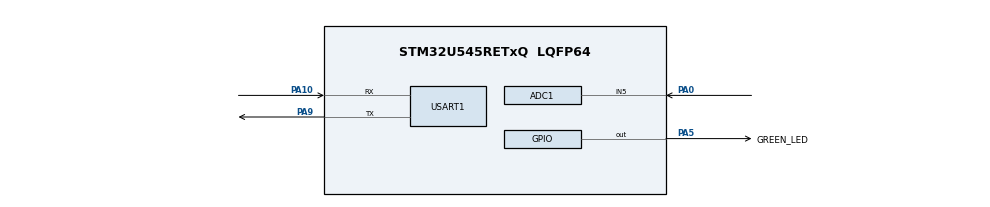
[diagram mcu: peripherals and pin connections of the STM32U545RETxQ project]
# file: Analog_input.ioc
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ADC1.Channel-0\#ChannelRegularConversion=ADC_CHANNEL_5
ADC1.MonitoredBy-0\#ChannelRegularConversion=__NULL
ADC1.NbrOfConversionFlag=1
ADC1.OffsetNumber-0\#ChannelRegularConversion=ADC_OFFSET_NONE
ADC1.Rank-0\#ChannelRegularConversion=1
ADC1.SamplingTime-0\#ChannelRegularConversion=ADC_SAMPLETIME_36CYCLES
ADC1.master=1
CORTEX_M33_NS.userName=CORTEX_M33
Mcu.Family=STM32U5
Mcu.Name=STM32U545RETxQ
Mcu.Package=LQFP64
NVIC.PriorityGroup=NVIC_PRIORITYGROUP_4
PA0.Mode=IN5-Single-Ended
PA0.Signal=ADC1_IN5
PA10.Mode=Asynchronous
PA10.Signal=USART1_RX
PA5.GPIO_Label=GREEN_LED
PA5.Signal=GPIO_Output
PA9.Mode=Asynchronous
PA9.Signal=USART1_TX
PWR.PowerMode=PWR_SMPS_SUPPLY
ProjectManager.HeapSize=0x200
ProjectManager.StackSize=0x400
ProjectManager.TargetToolchain=STM32CubeIDE
RCC.ADCFreq_Value=16000000
RCC.DACCLockSelectionVirtual=RCC_DAC1CLKSOURCE_LSI
RCC.DACCLockSelectionVirtualString=RCC_DAC1CLKSOURCE_LSI
RCC.EPOD_VALUE=4000000
RCC.HSE_VALUE=16000000
RCC.HSI48_VALUE=48000000
RCC.HSI_VALUE=16000000
RCC.LSE_VALUE=32768
RCC.LSIDIV_VALUE=32000
RCC.MSI_VALUE=4000000
RCC.USBFreq_Value=48000000
RCC.VCOOutputFreq_Value=516000000
USART1.VirtualMode-Asynchronous=VM_ASYNC
VP_ICACHE_VS_ICACHE.Mode=DirectMappedCache
VP_LPBAMQUEUE_VS_QUEUE.Mode=QUEUEMODE
VP_MEMORYMAP_VS_MEMORYMAP.Mode=CurAppReg
VP_NUCLEO-U545RE-Q_VS_BSP_COMMON.Mode=COMMON
VP_PWR_VS_LPOM.Mode=PowerOptimisation
VP_PWR_VS_SECSignals.Mode=Security/Privilege
VP_PWR_Vdda.Mode=isolationVdda
board=NUCLEO-U545RE-Q

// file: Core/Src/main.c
/* USER CODE BEGIN Header */
/**
  ******************************************************************************
  * @file           : main.c
  * @brief          : Main program body
  ******************************************************************************
  * @attention
  *
  * Copyright (c) 2026 STMicroelectronics.
  * All rights reserved.
  *
  * This software is licensed under terms that can be found in the LICENSE file
  * in the root directory of this software component.
  * If no LICENSE file comes with this software, it is provided AS-IS.
  *
  ******************************************************************************
  */
/* USER CODE END Header */
#include "main.h"

/* USER CODE BEGIN Includes */
#include <string.h>
#include <stdio.h>
/* USER CODE END Includes */

ADC_HandleTypeDef hadc1;

UART_HandleTypeDef huart1;

/* USER CODE BEGIN PV */
uint16_t measure = 0;
char msg[20];
/* USER CODE END PV */

void SystemClock_Config(void);
static void SystemPower_Config(void);
static void MX_GPIO_Init(void);
static void MX_ADC1_Init(void);
static void MX_ICACHE_Init(void);
static void MX_USART1_UART_Init(void);

int main(void)
{

  /* MCU Configuration--------------------------------------------------------*/

  /* Reset of all peripherals, Initializes the Flash interface and the Systick. */
  HAL_Init();

  /* Configure the System Power */
  SystemPower_Config();

  /* Configure the system clock */
  SystemClock_Config();

  /* Initialize all configured peripherals */
  MX_GPIO_Init();
  MX_ADC1_Init();
  MX_ICACHE_Init();
  MX_USART1_UART_Init();

  /* Infinite loop */
  while (1)
  {

    /* USER CODE BEGIN 3 */
	  HAL_ADC_Start(&hadc1);
	  HAL_ADC_PollForConversion(&hadc1, 20);
	  measure = HAL_ADC_GetValue(&hadc1);
	  sprintf(msg, "Value read: %hu\r\n", measure);
	  HAL_UART_Transmit(&huart1 , (uint8_t *)msg, strlen(msg), HAL_MAX_DELAY);
	  HAL_Delay(50);

  }
  /* USER CODE END 3 */
}

void SystemClock_Config(void)
{
  RCC_OscInitTypeDef RCC_OscInitStruct = {0};
  RCC_ClkInitTypeDef RCC_ClkInitStruct = {0};

  /** Configure the main internal regulator output voltage
  */
  if (HAL_PWREx_ControlVoltageScaling(PWR_REGULATOR_VOLTAGE_SCALE4) != HAL_OK)
  {
    Error_Handler();
  }

  /** Initializes the CPU, AHB and APB buses clocks
  */
  RCC_OscInitStruct.OscillatorType = RCC_OSCILLATORTYPE_HSI|RCC_OSCILLATORTYPE_MSI;
  RCC_OscInitStruct.HSIState = RCC_HSI_ON;
  RCC_OscInitStruct.HSICalibrationValue = RCC_HSICALIBRATION_DEFAULT;
  RCC_OscInitStruct.MSIState = RCC_MSI_ON;
  RCC_OscInitStruct.MSICalibrationValue = RCC_MSICALIBRATION_DEFAULT;
  RCC_OscInitStruct.MSIClockRange = RCC_MSIRANGE_4;
  RCC_OscInitStruct.PLL.PLLState = RCC_PLL_NONE;
  if (HAL_RCC_OscConfig(&RCC_OscInitStruct) != HAL_OK)
  {
    Error_Handler();
  }

  /** Initializes the CPU, AHB and APB buses clocks
  */
  RCC_ClkInitStruct.ClockType = RCC_CLOCKTYPE_HCLK|RCC_CLOCKTYPE_SYSCLK
                              |RCC_CLOCKTYPE_PCLK1|RCC_CLOCKTYPE_PCLK2
                              |RCC_CLOCKTYPE_PCLK3;
  RCC_ClkInitStruct.SYSCLKSource = RCC_SYSCLKSOURCE_MSI;
  RCC_ClkInitStruct.AHBCLKDivider = RCC_SYSCLK_DIV1;
  RCC_ClkInitStruct.APB1CLKDivider = RCC_HCLK_DIV1;
  RCC_ClkInitStruct.APB2CLKDivider = RCC_HCLK_DIV1;
  RCC_ClkInitStruct.APB3CLKDivider = RCC_HCLK_DIV1;

  if (HAL_RCC_ClockConfig(&RCC_ClkInitStruct, FLASH_LATENCY_0) != HAL_OK)
  {
    Error_Handler();
  }
}

/**
  * @brief Power Configuration
  * @retval None
  */
static void SystemPower_Config(void)
{

  /*
   * Switch to SMPS regulator instead of LDO
   */
  if (HAL_PWREx_ConfigSupply(PWR_SMPS_SUPPLY) != HAL_OK)
  {
    Error_Handler();
  }
}

static void MX_ADC1_Init(void)
{

  ADC_ChannelConfTypeDef sConfig = {0};

  /** Common config
  */
  hadc1.Instance = ADC1;
  hadc1.Init.ClockPrescaler = ADC_CLOCK_ASYNC_DIV1;
  hadc1.Init.Resolution = ADC_RESOLUTION_14B;
  hadc1.Init.GainCompensation = 0;
  hadc1.Init.DataAlign = ADC_DATAALIGN_RIGHT;
  hadc1.Init.ScanConvMode = ADC_SCAN_DISABLE;
  hadc1.Init.EOCSelection = ADC_EOC_SINGLE_CONV;
  hadc1.Init.LowPowerAutoWait = DISABLE;
  hadc1.Init.ContinuousConvMode = DISABLE;
  hadc1.Init.NbrOfConversion = 1;
  hadc1.Init.DiscontinuousConvMode = DISABLE;
  hadc1.Init.ExternalTrigConv = ADC_SOFTWARE_START;
  hadc1.Init.ExternalTrigConvEdge = ADC_EXTERNALTRIGCONVEDGE_NONE;
  hadc1.Init.DMAContinuousRequests = DISABLE;
  hadc1.Init.TriggerFrequencyMode = ADC_TRIGGER_FREQ_HIGH;
  hadc1.Init.Overrun = ADC_OVR_DATA_PRESERVED;
  hadc1.Init.LeftBitShift = ADC_LEFTBITSHIFT_NONE;
  hadc1.Init.ConversionDataManagement = ADC_CONVERSIONDATA_DR;
  hadc1.Init.OversamplingMode = DISABLE;
  if (HAL_ADC_Init(&hadc1) != HAL_OK)
  {
    Error_Handler();
  }

  /** Configure Regular Channel
  */
  sConfig.Channel = ADC_CHANNEL_5;
  sConfig.Rank = ADC_REGULAR_RANK_1;
  sConfig.SamplingTime = ADC_SAMPLETIME_36CYCLES;
  sConfig.SingleDiff = ADC_SINGLE_ENDED;
  sConfig.OffsetNumber = ADC_OFFSET_NONE;
  sConfig.Offset = 0;
  if (HAL_ADC_ConfigChannel(&hadc1, &sConfig) != HAL_OK)
  {
    Error_Handler();
  }

}

static void MX_ICACHE_Init(void)
{

  /** Enable instruction cache in 1-way (direct mapped cache)
  */
  if (HAL_ICACHE_ConfigAssociativityMode(ICACHE_1WAY) != HAL_OK)
  {
    Error_Handler();
  }
  if (HAL_ICACHE_Enable() != HAL_OK)
  {
    Error_Handler();
  }

}

static void MX_USART1_UART_Init(void)
{

  huart1.Instance = USART1;
  huart1.Init.BaudRate = 115200;
  huart1.Init.WordLength = UART_WORDLENGTH_8B;
  huart1.Init.StopBits = UART_STOPBITS_1;
  huart1.Init.Parity = UART_PARITY_NONE;
  huart1.Init.Mode = UART_MODE_TX_RX;
  huart1.Init.HwFlowCtl = UART_HWCONTROL_NONE;
  huart1.Init.OverSampling = UART_OVERSAMPLING_16;
  huart1.Init.OneBitSampling = UART_ONE_BIT_SAMPLE_DISABLE;
  huart1.Init.ClockPrescaler = UART_PRESCALER_DIV1;
  huart1.AdvancedInit.AdvFeatureInit = UART_ADVFEATURE_NO_INIT;
  if (HAL_UART_Init(&huart1) != HAL_OK)
  {
    Error_Handler();
  }
  if (HAL_UARTEx_SetTxFifoThreshold(&huart1, UART_TXFIFO_THRESHOLD_1_8) != HAL_OK)
  {
    Error_Handler();
  }
  if (HAL_UARTEx_SetRxFifoThreshold(&huart1, UART_RXFIFO_THRESHOLD_1_8) != HAL_OK)
  {
    Error_Handler();
  }
  if (HAL_UARTEx_DisableFifoMode(&huart1) != HAL_OK)
  {
    Error_Handler();
  }

}

static void MX_GPIO_Init(void)
{
  GPIO_InitTypeDef GPIO_InitStruct = {0};

  /* GPIO Ports Clock Enable */
  __HAL_RCC_GPIOA_CLK_ENABLE();

  /*Configure GPIO pin Output Level */
  HAL_GPIO_WritePin(GREEN_LED_GPIO_Port, GREEN_LED_Pin, GPIO_PIN_RESET);

  /*Configure GPIO pin : GREEN_LED_Pin */
  GPIO_InitStruct.Pin = GREEN_LED_Pin;
  GPIO_InitStruct.Mode = GPIO_MODE_OUTPUT_PP;
  GPIO_InitStruct.Pull = GPIO_NOPULL;
  GPIO_InitStruct.Speed = GPIO_SPEED_FREQ_LOW;
  HAL_GPIO_Init(GREEN_LED_GPIO_Port, &GPIO_InitStruct);

}

void Error_Handler(void)
{
  __disable_irq();
  while (1)
  {
  }
}
